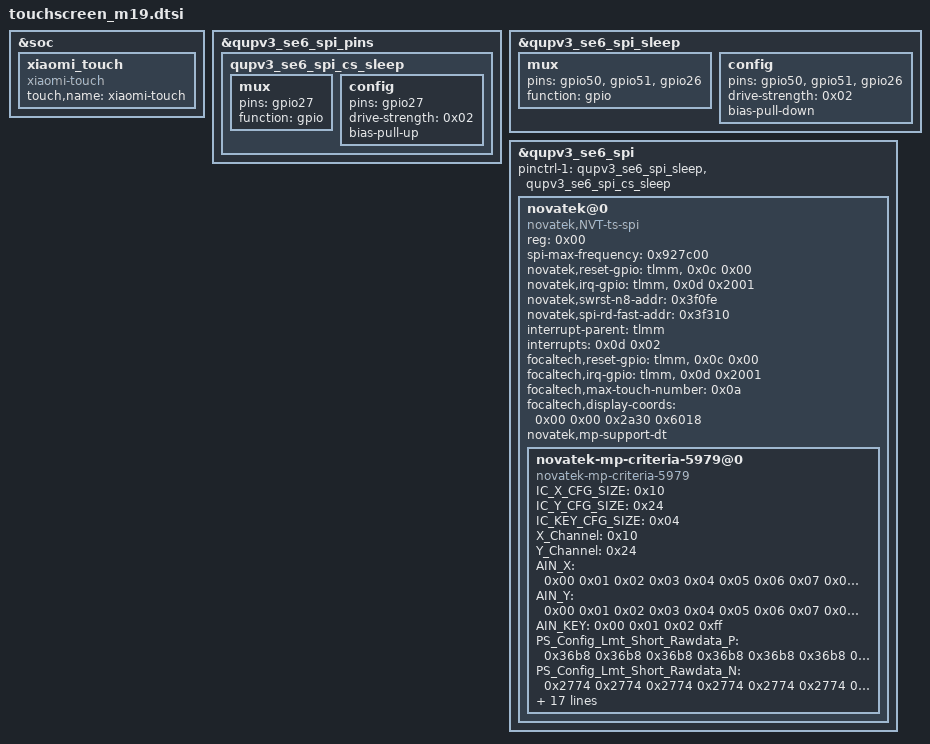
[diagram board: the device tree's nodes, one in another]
&soc {
	xiaomi_touch {
		status = "ok";
		compatible = "xiaomi-touch";
		touch,name = "xiaomi-touch";
	};
};

&qupv3_se6_spi_pins {
	qupv3_se6_spi_cs_sleep: qupv3_se6_spi_cs_sleep {
		mux {
			pins = "gpio27";
			function = "gpio";
		};

		config {
			pins = "gpio27";
			drive-strength = <0x02>;
			bias-pull-up;
		};
	};
};

&qupv3_se6_spi_sleep {
	mux {
		pins = "gpio50", "gpio51", "gpio26";
		function = "gpio";
	};

	config {
		pins = "gpio50", "gpio51", "gpio26";
		drive-strength = <0x02>;
		bias-pull-down;
	};
};


&qupv3_se6_spi {
			#address-cells = <0x01>;
			#size-cells = <0x00>;
			pinctrl-1 = <&qupv3_se6_spi_sleep>, <&qupv3_se6_spi_cs_sleep>;
			status = "okay";

			novatek@0 {
				compatible = "novatek,NVT-ts-spi", "focaltech,fts";
				reg = <0x00>;
				status = "ok";
				spi-max-frequency = <0x927c00>;
				novatek,reset-gpio = <&tlmm>, <0x0c 0x00>;
				novatek,irq-gpio = <&tlmm>, <0x0d 0x2001>;
				novatek,swrst-n8-addr = <0x3f0fe>;
				novatek,spi-rd-fast-addr = <0x3f310>;
				interrupt-parent = <&tlmm>;
				interrupts = <0x0d 0x02>;
				focaltech,reset-gpio = <&tlmm>, <0x0c 0x00>;
				focaltech,irq-gpio = <&tlmm>, <0x0d 0x2001>;
				focaltech,max-touch-number = <0x0a>;
				focaltech,display-coords = <0x00 0x00 0x2a30 0x6018>;
				novatek,mp-support-dt;

				novatek-mp-criteria-5979@0 {
					#address-cells = <0x01>;
					#size-cells = <0x00>;
					compatible = "novatek-mp-criteria-5979";
					IC_X_CFG_SIZE = <0x10>;
					IC_Y_CFG_SIZE = <0x24>;
					IC_KEY_CFG_SIZE = <0x04>;
					X_Channel = <0x10>;
					Y_Channel = <0x24>;
					AIN_X = <0x00 0x01 0x02 0x03 0x04 0x05 0x06 0x07 0x08 0x09 0x0a 0x0b 0x0c 0x0d 0x0e 0x0f>;
					AIN_Y = <0x00 0x01 0x02 0x03 0x04 0x05 0x06 0x07 0x08 0x09 0x0a 0x0b 0x0c 0x0d 0x0e 0x0f 0x10 0x11 0x12 0x13 0x14 0x15 0x16 0x17 0x18 0x19 0x1a 0x1b 0x1c 0x1d 0x1e 0x1f 0x20 0x21 0x22 0x23>;
					AIN_KEY = <0x00 0x01 0x02 0xff>;
					PS_Config_Lmt_Short_Rawdata_P = <0x36b8 0x36b8 0x36b8 0x36b8 0x36b8 0x36b8 0x36b8 0x36b8 0x36b8 0x36b8 0x36b8 0x36b8 0x36b8 0x36b8 0x36b8 0x36b8 0x36b8 0x36b8 0x36b8 0x36b8 0x36b8 0x36b8 0x36b8 0x36b8 0x36b8 0x36b8 0x36b8 0x36b8 0x36b8 0x36b8 0x36b8 0x36b8 0x36b8 0x36b8 0x36b8 0x36b8 0x36b8 0x36b8 0x36b8 0x36b8 0x36b8 0x36b8 0x36b8 0x36b8 0x36b8 0x36b8 0x36b8 0x36b8 0x36b8 0x36b8 0x36b8 0x36b8 0x36b8 0x36b8 0x36b8 0x36b8 0x36b8 0x36b8 0x36b8 0x36b8 0x36b8 0x36b8 0x36b8 0x36b8 0x36b8 0x36b8 0x36b8 0x36b8 0x36b8 0x36b8 0x36b8 0x36b8 0x36b8 0x36b8 0x36b8 0x36b8 0x36b8 0x36b8 0x36b8 0x36b8 0x36b8 0x36b8 0x36b8 0x36b8 0x36b8 0x36b8 0x36b8 0x36b8 0x36b8 0x36b8 0x36b8 0x36b8 0x36b8 0x36b8 0x36b8 0x36b8 0x36b8 0x36b8 0x36b8 0x36b8 0x36b8 0x36b8 0x36b8 0x36b8 0x36b8 0x36b8 0x36b8 0x36b8 0x36b8 0x36b8 0x36b8 0x36b8 0x36b8 0x36b8 0x36b8 0x36b8 0x36b8 0x36b8 0x36b8 0x36b8 0x36b8 0x36b8 0x36b8 0x36b8 0x36b8 0x36b8 0x36b8 0x36b8 0x36b8 0x36b8 0x36b8 0x36b8 0x36b8 0x36b8 0x36b8 0x36b8 0x36b8 0x36b8 0x36b8 0x36b8 0x36b8 0x36b8 0x36b8 0x36b8 0x36b8 0x36b8 0x36b8 0x36b8 0x36b8 0x36b8 0x36b8 0x36b8 0x36b8 0x36b8 0x36b8 0x36b8 0x36b8 0x36b8 0x36b8 0x36b8 0x36b8 0x36b8 0x36b8 0x36b8 0x36b8 0x36b8 0x36b8 0x36b8 0x36b8 0x36b8 0x36b8 0x36b8 0x36b8 0x36b8 0x36b8 0x36b8 0x36b8 0x36b8 0x36b8 0x36b8 0x36b8 0x36b8 0x36b8 0x36b8 0x36b8 0x36b8 0x36b8 0x36b8 0x36b8 0x36b8 0x36b8 0x36b8 0x36b8 0x36b8 0x36b8 0x36b8 0x36b8 0x36b8 0x36b8 0x36b8 0x36b8 0x36b8 0x36b8 0x36b8 0x36b8 0x36b8 0x36b8 0x36b8 0x36b8 0x36b8 0x36b8 0x36b8 0x36b8 0x36b8 0x36b8 0x36b8 0x36b8 0x36b8 0x36b8 0x36b8 0x36b8 0x36b8 0x36b8 0x36b8 0x36b8 0x36b8 0x36b8 0x36b8 0x36b8 0x36b8 0x36b8 0x36b8 0x36b8 0x36b8 0x36b8 0x36b8 0x36b8 0x36b8 0x36b8 0x36b8 0x36b8 0x36b8 0x36b8 0x36b8 0x36b8 0x36b8 0x36b8 0x36b8 0x36b8 0x36b8 0x36b8 0x36b8 0x36b8 0x36b8 0x36b8 0x36b8 0x36b8 0x36b8 0x36b8 0x36b8 0x36b8 0x36b8 0x36b8 0x36b8 0x36b8 0x36b8 0x36b8 0x36b8 0x36b8 0x36b8 0x36b8 0x36b8 0x36b8 0x36b8 0x36b8 0x36b8 0x36b8 0x36b8 0x36b8 0x36b8 0x36b8 0x36b8 0x36b8 0x36b8 0x36b8 0x36b8 0x36b8 0x36b8 0x36b8 0x36b8 0x36b8 0x36b8 0x36b8 0x36b8 0x36b8 0x36b8 0x36b8 0x36b8 0x36b8 0x36b8 0x36b8 0x36b8 0x36b8 0x36b8 0x36b8 0x36b8 0x36b8 0x36b8 0x36b8 0x36b8 0x36b8 0x36b8 0x36b8 0x36b8 0x36b8 0x36b8 0x36b8 0x36b8 0x36b8 0x36b8 0x36b8 0x36b8 0x36b8 0x36b8 0x36b8 0x36b8 0x36b8 0x36b8 0x36b8 0x36b8 0x36b8 0x36b8 0x36b8 0x36b8 0x36b8 0x36b8 0x36b8 0x36b8 0x36b8 0x36b8 0x36b8 0x36b8 0x36b8 0x36b8 0x36b8 0x36b8 0x36b8 0x36b8 0x36b8 0x36b8 0x36b8 0x36b8 0x36b8 0x36b8 0x36b8 0x36b8 0x36b8 0x36b8 0x36b8 0x36b8 0x36b8 0x36b8 0x36b8 0x36b8 0x36b8 0x36b8 0x36b8 0x36b8 0x36b8 0x36b8 0x36b8 0x36b8 0x36b8 0x36b8 0x36b8 0x36b8 0x36b8 0x36b8 0x36b8 0x36b8 0x36b8 0x36b8 0x36b8 0x36b8 0x36b8 0x36b8 0x36b8 0x36b8 0x36b8 0x36b8 0x36b8 0x36b8 0x36b8 0x36b8 0x36b8 0x36b8 0x36b8 0x36b8 0x36b8 0x36b8 0x36b8 0x36b8 0x36b8 0x36b8 0x36b8 0x36b8 0x36b8 0x36b8 0x36b8 0x36b8 0x36b8 0x36b8 0x36b8 0x36b8 0x36b8 0x36b8 0x36b8 0x36b8 0x36b8 0x36b8 0x36b8 0x36b8 0x36b8 0x36b8 0x36b8 0x36b8 0x36b8 0x36b8 0x36b8 0x36b8 0x36b8 0x36b8 0x36b8 0x36b8 0x36b8 0x36b8 0x36b8 0x36b8 0x36b8 0x36b8 0x36b8 0x36b8 0x36b8 0x36b8 0x36b8 0x36b8 0x36b8 0x36b8 0x36b8 0x36b8 0x36b8 0x36b8 0x36b8 0x36b8 0x36b8 0x36b8 0x36b8 0x36b8 0x36b8 0x36b8 0x36b8 0x36b8 0x36b8 0x36b8 0x36b8 0x36b8 0x36b8 0x36b8 0x36b8 0x36b8 0x36b8 0x36b8 0x36b8 0x36b8 0x36b8 0x36b8 0x36b8 0x36b8 0x36b8 0x36b8 0x36b8 0x36b8 0x36b8 0x36b8 0x36b8 0x36b8 0x36b8 0x36b8 0x36b8 0x36b8 0x36b8 0x36b8 0x36b8 0x36b8 0x36b8 0x36b8 0x36b8 0x36b8 0x36b8 0x36b8 0x36b8 0x36b8 0x36b8 0x36b8 0x36b8 0x36b8 0x36b8 0x36b8 0x36b8 0x36b8 0x36b8 0x36b8 0x36b8 0x36b8 0x36b8 0x36b8 0x36b8 0x36b8 0x36b8 0x36b8 0x36b8 0x36b8 0x36b8 0x36b8 0x36b8 0x36b8 0x36b8 0x36b8 0x36b8 0x36b8 0x36b8 0x36b8 0x36b8 0x36b8 0x36b8 0x36b8 0x36b8 0x36b8 0x36b8 0x36b8 0x36b8 0x36b8 0x36b8 0x36b8 0x36b8 0x36b8 0x36b8 0x36b8 0x36b8 0x36b8 0x36b8 0x36b8 0x36b8 0x36b8 0x36b8 0x36b8 0x36b8 0x36b8 0x36b8 0x36b8 0x36b8 0x36b8 0x36b8 0x36b8 0x36b8 0x36b8 0x36b8 0x36b8 0x36b8 0x36b8 0x36b8 0x36b8 0x36b8 0x36b8 0x36b8 0x36b8 0x36b8 0x36b8 0x36b8>;
					PS_Config_Lmt_Short_Rawdata_N = <0x2774 0x2774 0x2774 0x2774 0x2774 0x2774 0x2774 0x2774 0x2774 0x2774 0x2774 0x2774 0x2774 0x2774 0x2774 0x2774 0x2774 0x2774 0x2774 0x2774 0x2774 0x2774 0x2774 0x2774 0x2774 0x2774 0x2774 0x2774 0x2774 0x2774 0x2774 0x2774 0x2774 0x2774 0x2774 0x2774 0x2774 0x2774 0x2774 0x2774 0x2774 0x2774 0x2774 0x2774 0x2774 0x2774 0x2774 0x2774 0x2774 0x2774 0x2774 0x2774 0x2774 0x2774 0x2774 0x2774 0x2774 0x2774 0x2774 0x2774 0x2774 0x2774 0x2774 0x2774 0x2774 0x2774 0x2774 0x2774 0x2774 0x2774 0x2774 0x2774 0x2774 0x2774 0x2774 0x2774 0x2774 0x2774 0x2774 0x2774 0x2774 0x2774 0x2774 0x2774 0x2774 0x2774 0x2774 0x2774 0x2774 0x2774 0x2774 0x2774 0x2774 0x2774 0x2774 0x2774 0x2774 0x2774 0x2774 0x2774 0x2774 0x2774 0x2774 0x2774 0x2774 0x2774 0x2774 0x2774 0x2774 0x2774 0x2774 0x2774 0x2774 0x2774 0x2774 0x2774 0x2774 0x2774 0x2774 0x2774 0x2774 0x2774 0x2774 0x2774 0x2774 0x2774 0x2774 0x2774 0x2774 0x2774 0x2774 0x2774 0x2774 0x2774 0x2774 0x2774 0x2774 0x2774 0x2774 0x2774 0x2774 0x2774 0x2774 0x2774 0x2774 0x2774 0x2774 0x2774 0x2774 0x2774 0x2774 0x2774 0x2774 0x2774 0x2774 0x2774 0x2774 0x2774 0x2774 0x2774 0x2774 0x2774 0x2774 0x2774 0x2774 0x2774 0x2774 0x2774 0x2774 0x2774 0x2774 0x2774 0x2774 0x2774 0x2774 0x2774 0x2774 0x2774 0x2774 0x2774 0x2774 0x2774 0x2774 0x2774 0x2774 0x2774 0x2774 0x2774 0x2774 0x2774 0x2774 0x2774 0x2774 0x2774 0x2774 0x2774 0x2774 0x2774 0x2774 0x2774 0x2774 0x2774 0x2774 0x2774 0x2774 0x2774 0x2774 0x2774 0x2774 0x2774 0x2774 0x2774 0x2774 0x2774 0x2774 0x2774 0x2774 0x2774 0x2774 0x2774 0x2774 0x2774 0x2774 0x2774 0x2774 0x2774 0x2774 0x2774 0x2774 0x2774 0x2774 0x2774 0x2774 0x2774 0x2774 0x2774 0x2774 0x2774 0x2774 0x2774 0x2774 0x2774 0x2774 0x2774 0x2774 0x2774 0x2774 0x2774 0x2774 0x2774 0x2774 0x2774 0x2774 0x2774 0x2774 0x2774 0x2774 0x2774 0x2774 0x2774 0x2774 0x2774 0x2774 0x2774 0x2774 0x2774 0x2774 0x2774 0x2774 0x2774 0x2774 0x2774 0x2774 0x2774 0x2774 0x2774 0x2774 0x2774 0x2774 0x2774 0x2774 0x2774 0x2774 0x2774 0x2774 0x2774 0x2774 0x2774 0x2774 0x2774 0x2774 0x2774 0x2774 0x2774 0x2774 0x2774 0x2774 0x2774 0x2774 0x2774 0x2774 0x2774 0x2774 0x2774 0x2774 0x2774 0x2774 0x2774 0x2774 0x2774 0x2774 0x2774 0x2774 0x2774 0x2774 0x2774 0x2774 0x2774 0x2774 0x2774 0x2774 0x2774 0x2774 0x2774 0x2774 0x2774 0x2774 0x2774 0x2774 0x2774 0x2774 0x2774 0x2774 0x2774 0x2774 0x2774 0x2774 0x2774 0x2774 0x2774 0x2774 0x2774 0x2774 0x2774 0x2774 0x2774 0x2774 0x2774 0x2774 0x2774 0x2774 0x2774 0x2774 0x2774 0x2774 0x2774 0x2774 0x2774 0x2774 0x2774 0x2774 0x2774 0x2774 0x2774 0x2774 0x2774 0x2774 0x2774 0x2774 0x2774 0x2774 0x2774 0x2774 0x2774 0x2774 0x2774 0x2774 0x2774 0x2774 0x2774 0x2774 0x2774 0x2774 0x2774 0x2774 0x2774 0x2774 0x2774 0x2774 0x2774 0x2774 0x2774 0x2774 0x2774 0x2774 0x2774 0x2774 0x2774 0x2774 0x2774 0x2774 0x2774 0x2774 0x2774 0x2774 0x2774 0x2774 0x2774 0x2774 0x2774 0x2774 0x2774 0x2774 0x2774 0x2774 0x2774 0x2774 0x2774 0x2774 0x2774 0x2774 0x2774 0x2774 0x2774 0x2774 0x2774 0x2774 0x2774 0x2774 0x2774 0x2774 0x2774 0x2774 0x2774 0x2774 0x2774 0x2774 0x2774 0x2774 0x2774 0x2774 0x2774 0x2774 0x2774 0x2774 0x2774 0x2774 0x2774 0x2774 0x2774 0x2774 0x2774 0x2774 0x2774 0x2774 0x2774 0x2774 0x2774 0x2774 0x2774 0x2774 0x2774 0x2774 0x2774 0x2774 0x2774 0x2774 0x2774 0x2774 0x2774 0x2774 0x2774 0x2774 0x2774 0x2774 0x2774 0x2774 0x2774 0x2774 0x2774 0x2774 0x2774 0x2774 0x2774 0x2774 0x2774 0x2774 0x2774 0x2774 0x2774 0x2774 0x2774 0x2774 0x2774 0x2774 0x2774 0x2774 0x2774 0x2774 0x2774 0x2774 0x2774 0x2774 0x2774 0x2774 0x2774 0x2774 0x2774 0x2774 0x2774 0x2774 0x2774 0x2774 0x2774 0x2774 0x2774 0x2774 0x2774 0x2774 0x2774 0x2774 0x2774 0x2774 0x2774 0x2774 0x2774 0x2774 0x2774 0x2774 0x2774 0x2774 0x2774 0x2774 0x2774 0x2774 0x2774 0x2774 0x2774 0x2774 0x2774 0x2774 0x2774 0x2774 0x2774 0x2774 0x2774 0x2774 0x2774 0x2774 0x2774 0x2774 0x2774 0x2774 0x2774 0x2774 0x2774 0x2774 0x2774 0x2774 0x2774 0x2774 0x2774 0x2774 0x2774 0x2774 0x2774 0x2774 0x2774 0x2774 0x2774 0x2774 0x2774 0x2774 0x2774 0x2774 0x2774 0x2710 0x2710 0x2710>;
					PS_Config_Lmt_Open_Rawdata_P = <0xba7 0xbd9 0xc42 0xc75 0xc8b 0xc87 0xcbb 0xbe9 0xbd0 0xc55 0xc60 0xc42 0xc5c 0xc14 0xbd4 0xb99 0xbf8 0xc0c 0xc75 0xc9b 0xcbe 0xcb5 0xce2 0xc72 0xc49 0xc83 0xc8e 0xc6f 0xc86 0xc44 0xc0f 0xbf5 0xbfe 0xc24 0xc8e 0xcbe 0xce5 0xcd8 0xd0b 0xcd1 0xca3 0xcaa 0xcb7 0xc99 0xcb5 0xc60 0xc33 0xc11 0xc39 0xc44 0xcb2 0xcdf 0xd04 0xcf0 0xd1e 0xce1 0xcd4 0xcc3 0xcd4 0xcb8 0xcd3 0xc83 0xc59 0xc40 0xc50 0xc64 0xccc 0xcfb 0xd28 0xd16 0xd40 0xd02 0xd0c 0xcf7 0xd02 0xce9 0xcfb 0xca6 0xc7a 0xc63 0xc80 0xc73 0xcf0 0xd25 0xd59 0xd45 0xd67 0xd2b 0xd27 0xcf1 0xd13 0xcf7 0xd0d 0xcb2 0xc8a 0xc7a 0xc8e 0xcab 0xd0d 0xd3c 0xd78 0xd64 0xd8a 0xd43 0xd5f 0xd40 0xd47 0xd21 0xd30 0xcda 0xca7 0xc9c 0xcb1 0xcd0 0xd24 0xd59 0xda2 0xd8d 0xdb0 0xd61 0xd7d 0xd59 0xd4f 0xd37 0xd41 0xce6 0xcb7 0xcb5 0xcd8 0xd02 0xd67 0xd8a 0xdde 0xdc2 0xdf0 0xd98 0xdba 0xd8d 0xd97 0xd68 0xd6d 0xd0f 0xce5 0xcdc 0xcfa 0xd1d 0xd84 0xda5 0xdfb 0xdd7 0xe0b 0xdae 0xde8 0xdb8 0xdbb 0xd8b 0xd8a 0xd29 0xcfd 0xd04 0xd05 0xd40 0xda3 0xdad 0xe21 0xdfe 0xe2e 0xdd6 0xdf9 0xdd3 0xdd4 0xd8d 0xd98 0xd3d 0xd0b 0xd12 0xd21 0xd58 0xdb4 0xdde 0xe32 0xe0e 0xe3f 0xdde 0xe13 0xdeb 0xdec 0xdc5 0xdac 0xd4c 0xd1e 0xd2f 0xd4b 0xd89 0xded 0xe10 0xe5f 0xe48 0xe77 0xe04 0xe40 0xe17 0xe20 0xded 0xdc2 0xd72 0xd45 0xd4c 0xd68 0xda6 0xe10 0xe2e 0xe8c 0xe64 0xe9b 0xe1a 0xe5c 0xe33 0xe40 0xe0f 0xde5 0xd80 0xd58 0xd67 0xd6b 0xdb5 0xe1e 0xe40 0xea1 0xe77 0xeb3 0xe27 0xe8e 0xe60 0xe66 0xe38 0xe12 0xd9c 0xd7c 0xd84 0xd90 0xddb 0xe3f 0xe5d 0xec2 0xe74 0xed3 0xe46 0xeaa 0xe77 0xe82 0xe52 0xe23 0xd92 0xd8e 0xda2 0xd99 0xdf2 0xe4b 0xe6b 0xed6 0xeaf 0xeec 0xe58 0xecb 0xe9c 0xea1 0xe74 0xe3c 0xdc6 0xd90 0xdb1 0xdad 0xe09 0xe5b 0xe79 0xee8 0xec4 0xef3 0xe6d 0xed6 0xeac 0xeb0 0xe80 0xe4a 0xdda 0xd7c 0xda7 0xdf4 0xd8b 0xddf 0xddd 0xdf0 0xdd3 0xe0f 0xdf6 0xdaa 0xe08 0xe09 0xdd7 0xdf3 0xdc2 0xdd6 0xd8d 0xe41 0xdbf 0xe05 0xe04 0xe19 0xdfb 0xe35 0xe15 0xdd0 0xe23 0xe2e 0xdfa 0xe13 0xde2 0xdf3 0xdaa 0xe3a 0xddd 0xe15 0xe0f 0xe2a 0xe08 0xe44 0xe05 0xdf3 0xe3d 0xe51 0xe21 0xe3a 0xe0c 0xe19 0xda2 0xe4a 0xded 0xe27 0xe1a 0xe36 0xe19 0xe55 0xe25 0xe01 0xe4b 0xe62 0xe36 0xe4f 0xe21 0xe24 0xdd6 0xe55 0xe12 0xe46 0xe38 0xe58 0xe32 0xe6b 0xe3a 0xe20 0xe69 0xe78 0xe5b 0xe70 0xe39 0xe3f 0xde8 0xe64 0xe23 0xe56 0xe4e 0xe67 0xe44 0xe7e 0xe4d 0xe32 0xe6d 0xe80 0xe5f 0xe74 0xe3d 0xe41 0xdf2 0xe62 0xe35 0xe67 0xe5f 0xe7b 0xe58 0xe8d 0xe5d 0xe4f 0xe85 0xe94 0xe77 0xe8e 0xe60 0xe60 0xe0b 0xe8e 0xe64 0xe91 0xe8a 0xea6 0xe83 0xeb1 0xe85 0xe60 0xe89 0xe9a 0xe79 0xe93 0xe5f 0xe60 0xe0b 0xe6e 0xe54 0xe85 0xe7e 0xe9b 0xe71 0xea6 0xe77 0xe78 0xe9e 0xeb7 0xe95 0xeb1 0xe7b 0xe83 0xe20 0xe87 0xe6a 0xe9e 0xe93 0xeb3 0xe8c 0xebf 0xe8a 0xe7e 0xe9f 0xeb4 0xe94 0xeac 0xe7c 0xe82 0xe2a 0xe90 0xe8c 0xeb7 0xeb6 0xecc 0xea5 0xed9 0xea1 0xe90 0xeb1 0xec2 0xeaa 0xec1 0xe91 0xe94 0xe33 0xe8a 0xe82 0xeb3 0xeb7 0xecc 0xe9f 0xed9 0xe9e 0xe8e 0xea9 0xeb7 0xe9f 0xeb8 0xe87 0xe87 0xe38 0xe85 0xe8e 0xec5 0xebf 0xed6 0xead 0xee2 0xea2 0xe9c 0xeb7 0xecc 0xeaf 0xec5 0xe9e 0xe8e 0xe41 0xe89 0xe93 0xecd 0xec9 0xede 0xeb8 0xee7 0xea6 0xea3 0xebb 0xecb 0xeb3 0xec9 0xe9e 0xe90 0xe4a 0xe94 0xea8 0xeeb 0xee2 0xefa 0xed2 0xf03 0xebb 0xebb 0xecf 0xede 0xec2 0xedb 0xeb0 0xe9e 0xe51 0xec6 0xed9 0xf27 0xf23 0xf32 0xf11 0xf47 0xefc 0xefe 0xf12 0xf1c 0xf01 0xf16 0xee7 0xecf 0xe86 0xe91 0xed9 0xf26 0xf23 0xf35 0xf13 0xf46 0xefc 0xf07 0xf20 0xf23 0xf0f 0xf24 0xef7 0xed3 0xe67 0xcea 0xdd1 0xe80 0xf59 0xf6a 0xf44 0xf75 0xf24 0xf2a 0xf47 0xf4a 0xf31 0xf47 0xe63 0xd89 0xce2 0x1400 0x1400 0x1400>;
					PS_Config_Lmt_Open_Rawdata_N = <0x4fe 0x514 0x541 0x556 0x560 0x55e 0x574 0x51a 0x510 0x549 0x54d 0x541 0x54c 0x52d 0x511 0x4f8 0x521 0x529 0x556 0x567 0x576 0x572 0x585 0x555 0x544 0x55c 0x561 0x554 0x55e 0x541 0x52b 0x520 0x523 0x534 0x561 0x576 0x586 0x581 0x597 0x57e 0x56a 0x56d 0x573 0x566 0x572 0x54d 0x53a 0x52c 0x53d 0x541 0x571 0x584 0x594 0x58b 0x59f 0x585 0x57f 0x578 0x57f 0x573 0x57f 0x55c 0x54a 0x540 0x547 0x54f 0x57c 0x590 0x5a3 0x59b 0x5ad 0x593 0x597 0x58e 0x593 0x588 0x590 0x56b 0x559 0x54f 0x55b 0x556 0x58b 0x5a2 0x5b8 0x5b0 0x5be 0x5a4 0x5a3 0x58c 0x59a 0x58e 0x598 0x571 0x55f 0x559 0x561 0x56e 0x598 0x5ac 0x5c5 0x5bd 0x5cd 0x5af 0x5bb 0x5ad 0x5b0 0x5a0 0x5a7 0x582 0x56c 0x567 0x570 0x57d 0x5a1 0x5b8 0x5d7 0x5ce 0x5dd 0x5bc 0x5c8 0x5b8 0x5b4 0x5aa 0x5ae 0x587 0x573 0x572 0x581 0x593 0x5be 0x5cd 0x5f1 0x5e5 0x5f9 0x5d3 0x5e2 0x5ce 0x5d3 0x5bf 0x5c1 0x598 0x586 0x583 0x58f 0x59e 0x5cb 0x5d9 0x5fe 0x5ee 0x604 0x5dd 0x5f5 0x5e1 0x5e2 0x5ce 0x5cd 0x5a4 0x591 0x594 0x594 0x5ad 0x5d8 0x5dc 0x60e 0x5ff 0x613 0x5ee 0x5fd 0x5ec 0x5ed 0x5ce 0x5d3 0x5ac 0x597 0x59a 0x5a0 0x5b8 0x5df 0x5f1 0x615 0x606 0x61b 0x5f1 0x608 0x5f7 0x5f7 0x5e6 0x5dc 0x5b3 0x59f 0x5a6 0x5b2 0x5cd 0x5f8 0x607 0x628 0x61f 0x633 0x601 0x61b 0x60a 0x60d 0x5f8 0x5e5 0x5c3 0x5b0 0x5b3 0x5bf 0x5d9 0x607 0x613 0x63c 0x62b 0x642 0x60b 0x627 0x616 0x61b 0x606 0x5f4 0x5c9 0x5b8 0x5be 0x5c0 0x5e0 0x60d 0x61b 0x645 0x633 0x64c 0x610 0x63d 0x629 0x62b 0x618 0x607 0x5d5 0x5c7 0x5cb 0x5d0 0x5f0 0x61b 0x628 0x653 0x631 0x65a 0x61e 0x649 0x633 0x637 0x623 0x60f 0x5d1 0x5cf 0x5d7 0x5d4 0x5fa 0x620 0x62e 0x65b 0x64b 0x665 0x625 0x657 0x643 0x645 0x631 0x619 0x5e7 0x5d0 0x5de 0x5dc 0x604 0x627 0x634 0x663 0x654 0x668 0x62e 0x65b 0x649 0x64b 0x637 0x61f 0x5ef 0x5c7 0x5da 0x5fb 0x5ce 0x5f2 0x5f1 0x5f9 0x5ec 0x606 0x5fb 0x5db 0x603 0x604 0x5ee 0x5fa 0x5e5 0x5ee 0x5ce 0x61c 0x5e4 0x602 0x601 0x60a 0x5fe 0x616 0x609 0x5eb 0x60f 0x613 0x5fd 0x608 0x5f3 0x5fa 0x5db 0x619 0x5f1 0x609 0x606 0x612 0x603 0x61d 0x602 0x5fa 0x61a 0x622 0x60e 0x619 0x605 0x60a 0x5d7 0x61f 0x5f8 0x610 0x60b 0x617 0x60a 0x624 0x610 0x600 0x620 0x62a 0x617 0x622 0x60e 0x60f 0x5ee 0x624 0x607 0x61e 0x618 0x625 0x615 0x62e 0x619 0x60d 0x62d 0x633 0x627 0x630 0x618 0x61b 0x5f5 0x62b 0x60f 0x625 0x621 0x62c 0x61d 0x636 0x621 0x615 0x62e 0x637 0x628 0x631 0x61a 0x61c 0x5fa 0x62a 0x616 0x62c 0x628 0x634 0x625 0x63c 0x628 0x622 0x639 0x63f 0x633 0x63d 0x629 0x629 0x604 0x63d 0x62b 0x63e 0x63b 0x647 0x638 0x64c 0x639 0x629 0x63a 0x642 0x634 0x63f 0x628 0x629 0x604 0x62f 0x624 0x639 0x636 0x642 0x630 0x647 0x633 0x633 0x643 0x64e 0x640 0x64c 0x634 0x638 0x60d 0x63a 0x62d 0x643 0x63f 0x64c 0x63c 0x652 0x63b 0x636 0x644 0x64d 0x63f 0x649 0x635 0x637 0x612 0x63d 0x63c 0x64e 0x64e 0x657 0x646 0x65d 0x645 0x63d 0x64c 0x653 0x649 0x652 0x63e 0x63f 0x616 0x63b 0x637 0x64c 0x64e 0x657 0x644 0x65d 0x643 0x63d 0x648 0x64e 0x644 0x64f 0x63a 0x63a 0x618 0x639 0x63d 0x654 0x652 0x65b 0x64a 0x661 0x645 0x643 0x64e 0x657 0x64b 0x654 0x643 0x63d 0x61c 0x63a 0x63f 0x658 0x656 0x65f 0x64f 0x663 0x647 0x646 0x650 0x657 0x64c 0x656 0x643 0x63d 0x61f 0x63f 0x648 0x664 0x661 0x66b 0x65a 0x66f 0x650 0x650 0x658 0x65f 0x653 0x65e 0x64b 0x643 0x622 0x655 0x65d 0x67e 0x67c 0x683 0x675 0x68c 0x66c 0x66d 0x675 0x679 0x66e 0x677 0x663 0x658 0x639 0x63e 0x65d 0x67e 0x67c 0x684 0x676 0x68b 0x66c 0x670 0x67b 0x67c 0x674 0x67d 0x66a 0x65a 0x62c 0x589 0x5ec 0x637 0x694 0x69b 0x68b 0x6a0 0x67d 0x67f 0x68c 0x68d 0x682 0x68c 0x62a 0x5cd 0x585 0xfffffe01 0xfffffe01 0xfffffe01>;
					PS_Config_Lmt_FW_Rawdata_P = <0x460 0x454 0x453 0x45a 0x452 0x45a 0x457 0x459 0x468 0x467 0x465 0x45b 0x467 0x462 0x453 0x454 0x45e 0x456 0x456 0x45a 0x457 0x45a 0x457 0x45d 0x460 0x457 0x457 0x460 0x45a 0x45e 0x45e 0x45e 0x45b 0x461 0x461 0x45e 0x45e 0x45d 0x45e 0x459 0x450 0x44f 0x44c 0x453 0x44f 0x44f 0x452 0x45b 0x464 0x454 0x459 0x459 0x453 0x45a 0x457 0x460 0x460 0x45e 0x45d 0x45d 0x45b 0x457 0x457 0x462 0x45b 0x459 0x457 0x457 0x456 0x457 0x456 0x459 0x45d 0x453 0x457 0x45b 0x457 0x453 0x457 0x469 0x461 0x45d 0x461 0x45b 0x460 0x460 0x460 0x457 0x454 0x452 0x450 0x450 0x450 0x453 0x456 0x462 0x460 0x457 0x454 0x457 0x459 0x456 0x457 0x457 0x45b 0x457 0x454 0x453 0x457 0x454 0x457 0x462 0x465 0x459 0x459 0x45a 0x456 0x45b 0x459 0x460 0x460 0x45b 0x45d 0x45b 0x45e 0x45d 0x45d 0x45e 0x45e 0x44c 0x453 0x450 0x457 0x456 0x456 0x456 0x454 0x456 0x456 0x457 0x454 0x456 0x454 0x461 0x46c 0x453 0x454 0x456 0x453 0x45a 0x454 0x45b 0x457 0x457 0x459 0x459 0x454 0x459 0x454 0x462 0x45e 0x454 0x450 0x452 0x450 0x454 0x453 0x457 0x45a 0x452 0x453 0x452 0x454 0x450 0x454 0x45d 0x461 0x457 0x459 0x459 0x454 0x45d 0x45a 0x460 0x457 0x457 0x453 0x453 0x456 0x457 0x457 0x462 0x468 0x453 0x452 0x453 0x454 0x459 0x457 0x45d 0x45b 0x45a 0x459 0x459 0x45d 0x45b 0x45e 0x45d 0x462 0x45b 0x45d 0x45d 0x45b 0x45b 0x45d 0x460 0x457 0x454 0x456 0x457 0x457 0x45a 0x45a 0x465 0x461 0x45b 0x45b 0x45b 0x45d 0x456 0x457 0x460 0x462 0x464 0x462 0x461 0x468 0x45d 0x460 0x461 0x460 0x45d 0x461 0x462 0x45e 0x468 0x469 0x460 0x456 0x456 0x457 0x453 0x457 0x454 0x454 0x45e 0x45e 0x452 0x44f 0x44f 0x450 0x456 0x454 0x45d 0x453 0x450 0x45a 0x45d 0x459 0x460 0x456 0x465 0x462 0x453 0x456 0x45a 0x45e 0x461 0x464 0x460 0x45d 0x45e 0x459 0x459 0x459 0x45b 0x45b 0x464 0x461 0x457 0x45a 0x45d 0x45a 0x45d 0x462 0x45d 0x465 0x45d 0x45b 0x454 0x459 0x454 0x453 0x464 0x46b 0x453 0x459 0x457 0x457 0x456 0x456 0x453 0x45d 0x45b 0x45b 0x459 0x45a 0x45b 0x45d 0x45b 0x45e 0x450 0x454 0x453 0x456 0x456 0x454 0x456 0x45d 0x460 0x45e 0x465 0x45e 0x45d 0x45d 0x45d 0x456 0x457 0x456 0x454 0x450 0x452 0x462 0x461 0x462 0x461 0x460 0x454 0x45a 0x457 0x45a 0x465 0x468 0x450 0x44f 0x450 0x450 0x454 0x459 0x45b 0x46b 0x462 0x467 0x45a 0x461 0x460 0x45a 0x45e 0x464 0x461 0x464 0x464 0x461 0x460 0x45e 0x45e 0x45d 0x461 0x461 0x461 0x461 0x461 0x461 0x459 0x460 0x454 0x457 0x456 0x457 0x453 0x461 0x460 0x462 0x462 0x462 0x460 0x461 0x464 0x465 0x45b 0x460 0x462 0x462 0x465 0x462 0x45e 0x461 0x461 0x465 0x462 0x464 0x45e 0x465 0x465 0x464 0x45e 0x460 0x467 0x461 0x465 0x464 0x462 0x45a 0x45d 0x468 0x467 0x468 0x465 0x467 0x467 0x46c 0x459 0x45e 0x465 0x464 0x464 0x467 0x465 0x460 0x461 0x462 0x462 0x462 0x45e 0x462 0x468 0x465 0x45b 0x45d 0x45a 0x460 0x456 0x45e 0x457 0x45b 0x456 0x45b 0x459 0x459 0x459 0x45a 0x45b 0x461 0x467 0x462 0x460 0x45e 0x464 0x461 0x45d 0x461 0x460 0x45b 0x45b 0x45a 0x45d 0x45d 0x45a 0x45a 0x462 0x464 0x454 0x459 0x452 0x459 0x459 0x453 0x457 0x456 0x456 0x456 0x457 0x453 0x452 0x452 0x46b 0x465 0x453 0x45d 0x453 0x45e 0x452 0x450 0x454 0x465 0x45a 0x459 0x45b 0x45a 0x45a 0x45d 0x45e 0x467 0x45e 0x45a 0x45e 0x459 0x457 0x462 0x45d 0x45e 0x45e 0x45e 0x45e 0x45e 0x464 0x462 0x464 0x45e 0x45a 0x462 0x45e 0x45e 0x45e 0x461 0x460 0x461 0x45b 0x456 0x45a 0x45a 0x462 0x45e 0x467 0x45e 0x459 0x460 0x457 0x45a 0x454 0x45b 0x457 0x45e 0x460 0x45b 0x45e 0x460 0x461 0x45d 0x467 0x45e 0x45e 0x45e 0x460 0x461 0x45b 0x45e 0x464 0x45e 0x46b 0x462 0x469 0x464 0x45e 0x45b 0x457 0xf00 0xf00 0xf00>;
					PS_Config_Lmt_FW_Rawdata_N = <0x1e0 0x1db 0x1da 0x1dd 0x1da 0x1dd 0x1dc 0x1dd 0x1e3 0x1e3 0x1e2 0x1de 0x1e3 0x1e1 0x1da 0x1db 0x1df 0x1db 0x1db 0x1dd 0x1dc 0x1dd 0x1dc 0x1de 0x1e0 0x1dc 0x1dc 0x1e0 0x1dd 0x1df 0x1df 0x1df 0x1de 0x1e0 0x1e0 0x1df 0x1df 0x1de 0x1df 0x1dd 0x1d9 0x1d8 0x1d7 0x1da 0x1d8 0x1d8 0x1da 0x1de 0x1e1 0x1db 0x1dd 0x1dd 0x1da 0x1dd 0x1dc 0x1e0 0x1e0 0x1df 0x1de 0x1de 0x1de 0x1dc 0x1dc 0x1e1 0x1de 0x1dd 0x1dc 0x1dc 0x1db 0x1dc 0x1db 0x1dd 0x1de 0x1da 0x1dc 0x1de 0x1dc 0x1da 0x1dc 0x1e4 0x1e0 0x1de 0x1e0 0x1de 0x1e0 0x1e0 0x1e0 0x1dc 0x1db 0x1da 0x1d9 0x1d9 0x1d9 0x1da 0x1db 0x1e1 0x1e0 0x1dc 0x1db 0x1dc 0x1dd 0x1db 0x1dc 0x1dc 0x1de 0x1dc 0x1db 0x1da 0x1dc 0x1db 0x1dc 0x1e1 0x1e2 0x1dd 0x1dd 0x1dd 0x1db 0x1de 0x1dd 0x1e0 0x1e0 0x1de 0x1de 0x1de 0x1df 0x1de 0x1de 0x1df 0x1df 0x1d7 0x1da 0x1d9 0x1dc 0x1db 0x1db 0x1db 0x1db 0x1db 0x1db 0x1dc 0x1db 0x1db 0x1db 0x1e0 0x1e5 0x1da 0x1db 0x1db 0x1da 0x1dd 0x1db 0x1de 0x1dc 0x1dc 0x1dd 0x1dd 0x1db 0x1dd 0x1db 0x1e1 0x1df 0x1db 0x1d9 0x1da 0x1d9 0x1db 0x1da 0x1dc 0x1dd 0x1da 0x1da 0x1da 0x1db 0x1d9 0x1db 0x1de 0x1e0 0x1dc 0x1dd 0x1dd 0x1db 0x1de 0x1dd 0x1e0 0x1dc 0x1dc 0x1da 0x1da 0x1db 0x1dc 0x1dc 0x1e1 0x1e3 0x1da 0x1da 0x1da 0x1db 0x1dd 0x1dc 0x1de 0x1de 0x1dd 0x1dd 0x1dd 0x1de 0x1de 0x1df 0x1de 0x1e1 0x1de 0x1de 0x1de 0x1de 0x1de 0x1de 0x1e0 0x1dc 0x1db 0x1db 0x1dc 0x1dc 0x1dd 0x1dd 0x1e2 0x1e0 0x1de 0x1de 0x1de 0x1de 0x1db 0x1dc 0x1e0 0x1e1 0x1e1 0x1e1 0x1e0 0x1e3 0x1de 0x1e0 0x1e0 0x1e0 0x1de 0x1e0 0x1e1 0x1df 0x1e3 0x1e4 0x1e0 0x1db 0x1db 0x1dc 0x1da 0x1dc 0x1db 0x1db 0x1df 0x1df 0x1da 0x1d8 0x1d8 0x1d9 0x1db 0x1db 0x1de 0x1da 0x1d9 0x1dd 0x1de 0x1dd 0x1e0 0x1db 0x1e2 0x1e1 0x1da 0x1db 0x1dd 0x1df 0x1e0 0x1e1 0x1e0 0x1de 0x1df 0x1dd 0x1dd 0x1dd 0x1de 0x1de 0x1e1 0x1e0 0x1dc 0x1dd 0x1de 0x1dd 0x1de 0x1e1 0x1de 0x1e2 0x1de 0x1de 0x1db 0x1dd 0x1db 0x1da 0x1e1 0x1e4 0x1da 0x1dd 0x1dc 0x1dc 0x1db 0x1db 0x1da 0x1de 0x1de 0x1de 0x1dd 0x1dd 0x1de 0x1de 0x1de 0x1df 0x1d9 0x1db 0x1da 0x1db 0x1db 0x1db 0x1db 0x1de 0x1e0 0x1df 0x1e2 0x1df 0x1de 0x1de 0x1de 0x1db 0x1dc 0x1db 0x1db 0x1d9 0x1da 0x1e1 0x1e0 0x1e1 0x1e0 0x1e0 0x1db 0x1dd 0x1dc 0x1dd 0x1e2 0x1e3 0x1d9 0x1d8 0x1d9 0x1d9 0x1db 0x1dd 0x1de 0x1e4 0x1e1 0x1e3 0x1dd 0x1e0 0x1e0 0x1dd 0x1df 0x1e1 0x1e0 0x1e1 0x1e1 0x1e0 0x1e0 0x1df 0x1df 0x1de 0x1e0 0x1e0 0x1e0 0x1e0 0x1e0 0x1e0 0x1dd 0x1e0 0x1db 0x1dc 0x1db 0x1dc 0x1da 0x1e0 0x1e0 0x1e1 0x1e1 0x1e1 0x1e0 0x1e0 0x1e1 0x1e2 0x1de 0x1e0 0x1e1 0x1e1 0x1e2 0x1e1 0x1df 0x1e0 0x1e0 0x1e2 0x1e1 0x1e1 0x1df 0x1e2 0x1e2 0x1e1 0x1df 0x1e0 0x1e3 0x1e0 0x1e2 0x1e1 0x1e1 0x1dd 0x1de 0x1e3 0x1e3 0x1e3 0x1e2 0x1e3 0x1e3 0x1e5 0x1dd 0x1df 0x1e2 0x1e1 0x1e1 0x1e3 0x1e2 0x1e0 0x1e0 0x1e1 0x1e1 0x1e1 0x1df 0x1e1 0x1e3 0x1e2 0x1de 0x1de 0x1dd 0x1e0 0x1db 0x1df 0x1dc 0x1de 0x1db 0x1de 0x1dd 0x1dd 0x1dd 0x1dd 0x1de 0x1e0 0x1e3 0x1e1 0x1e0 0x1df 0x1e1 0x1e0 0x1de 0x1e0 0x1e0 0x1de 0x1de 0x1dd 0x1de 0x1de 0x1dd 0x1dd 0x1e1 0x1e1 0x1db 0x1dd 0x1da 0x1dd 0x1dd 0x1da 0x1dc 0x1db 0x1db 0x1db 0x1dc 0x1da 0x1da 0x1da 0x1e4 0x1e2 0x1da 0x1de 0x1da 0x1df 0x1da 0x1d9 0x1db 0x1e2 0x1dd 0x1dd 0x1de 0x1dd 0x1dd 0x1de 0x1df 0x1e3 0x1df 0x1dd 0x1df 0x1dd 0x1dc 0x1e1 0x1de 0x1df 0x1df 0x1df 0x1df 0x1df 0x1e1 0x1e1 0x1e1 0x1df 0x1dd 0x1e1 0x1df 0x1df 0x1df 0x1e0 0x1e0 0x1e0 0x1de 0x1db 0x1dd 0x1dd 0x1e1 0x1df 0x1e3 0x1df 0x1dd 0x1e0 0x1dc 0x1dd 0x1db 0x1de 0x1dc 0x1df 0x1e0 0x1de 0x1df 0x1e0 0x1e0 0x1de 0x1e3 0x1df 0x1df 0x1df 0x1e0 0x1e0 0x1de 0x1df 0x1e1 0x1df 0x1e4 0x1e1 0x1e4 0x1e1 0x1df 0x1de 0x1dc 0xf0 0xf0 0xf0>;
					PS_Config_Lmt_FW_CC_P = <0x29 0x2a 0x2a 0x2a 0x2a 0x2a 0x2a 0x2a 0x2a 0x2a 0x2a 0x2a 0x2a 0x2a 0x2a 0x29 0x2a 0x2a 0x2a 0x2a 0x29 0x2a 0x2a 0x2a 0x2a 0x29 0x29 0x29 0x29 0x29 0x29 0x2a 0x2a 0x29 0x29 0x29 0x29 0x29 0x29 0x29 0x2a 0x2a 0x2a 0x29 0x2a 0x2a 0x29 0x2a 0x2c 0x2a 0x2a 0x2a 0x2a 0x2a 0x2a 0x2a 0x2a 0x2a 0x2a 0x2a 0x2a 0x2a 0x2a 0x2a 0x2a 0x29 0x29 0x2a 0x29 0x2a 0x29 0x2a 0x2a 0x2a 0x2a 0x2a 0x2a 0x2a 0x2a 0x2a 0x2c 0x2a 0x2a 0x2a 0x2a 0x2a 0x2a 0x2a 0x2a 0x2a 0x2a 0x2a 0x2a 0x2a 0x2a 0x2a 0x2a 0x2a 0x29 0x29 0x29 0x29 0x29 0x29 0x2a 0x2a 0x2a 0x2a 0x2a 0x2a 0x2a 0x2a 0x2c 0x2a 0x2a 0x2a 0x2a 0x2a 0x2a 0x2a 0x2a 0x2a 0x2a 0x2a 0x2a 0x2a 0x2a 0x2c 0x2a 0x2a 0x2a 0x2a 0x2a 0x2a 0x2a 0x2a 0x2a 0x2a 0x2a 0x2a 0x2a 0x2a 0x2a 0x2c 0x2a 0x2a 0x2a 0x2a 0x2a 0x2a 0x2a 0x2a 0x2a 0x2a 0x2a 0x2a 0x2a 0x2a 0x2a 0x2c 0x2a 0x2a 0x2a 0x2a 0x2a 0x2a 0x2a 0x2a 0x2a 0x2a 0x2a 0x2a 0x2a 0x2a 0x2a 0x2c 0x2c 0x2a 0x2a 0x2a 0x2a 0x2a 0x2a 0x2a 0x2a 0x2a 0x2a 0x2a 0x2a 0x2a 0x2a 0x2c 0x2a 0x2a 0x2a 0x2a 0x2a 0x2a 0x2a 0x2a 0x2a 0x2a 0x2a 0x2a 0x2a 0x2a 0x2a 0x2c 0x2c 0x2a 0x2a 0x2a 0x2a 0x2a 0x2a 0x2c 0x2a 0x2a 0x2a 0x2a 0x2a 0x2a 0x2a 0x2c 0x2a 0x2a 0x2a 0x2a 0x2a 0x2a 0x2a 0x2a 0x2a 0x2a 0x2a 0x2a 0x2a 0x2a 0x2a 0x2c 0x2c 0x2a 0x2a 0x2a 0x2a 0x2a 0x2a 0x2c 0x2a 0x2a 0x2a 0x2a 0x2a 0x2a 0x2a 0x2c 0x2a 0x2a 0x2a 0x2a 0x2a 0x2a 0x2a 0x2a 0x2a 0x2a 0x2a 0x2a 0x2a 0x2a 0x2a 0x2c 0x2c 0x2a 0x2a 0x2a 0x2a 0x2a 0x2a 0x2c 0x2a 0x2a 0x2a 0x2a 0x2a 0x2a 0x2a 0x2c 0x2c 0x2a 0x29 0x29 0x29 0x2a 0x2a 0x29 0x2a 0x2a 0x2a 0x2a 0x2a 0x2a 0x2a 0x2c 0x2c 0x2a 0x2a 0x2a 0x2a 0x2a 0x2a 0x2a 0x2c 0x2a 0x2a 0x2a 0x2a 0x2a 0x2a 0x2c 0x2c 0x2a 0x2a 0x2a 0x2a 0x2a 0x2a 0x2a 0x2a 0x2a 0x2a 0x2a 0x2a 0x2a 0x2a 0x2c 0x2c 0x2a 0x2a 0x2a 0x2a 0x2a 0x2a 0x2a 0x2c 0x2a 0x2a 0x2a 0x2a 0x2a 0x2a 0x2c 0x2c 0x2a 0x2a 0x2a 0x2a 0x2a 0x2a 0x2a 0x2a 0x2a 0x2a 0x2a 0x2a 0x2a 0x2a 0x2c 0x2c 0x2a 0x2a 0x2a 0x2a 0x2a 0x2c 0x2c 0x2c 0x2a 0x2a 0x2a 0x2a 0x2a 0x2a 0x2c 0x2c 0x2a 0x2a 0x2a 0x2a 0x2a 0x2a 0x2a 0x2c 0x2a 0x2a 0x2a 0x2a 0x2a 0x2a 0x2c 0x2d 0x2a 0x2a 0x2a 0x2a 0x2a 0x2c 0x2c 0x2c 0x2a 0x2a 0x2a 0x2a 0x2a 0x2a 0x2c 0x2c 0x2a 0x2a 0x2a 0x2a 0x2a 0x2a 0x2a 0x2a 0x2a 0x2c 0x2a 0x2c 0x2c 0x2c 0x2c 0x2d 0x2a 0x2c 0x2a 0x2a 0x2a 0x2c 0x2c 0x2c 0x2a 0x2a 0x2a 0x2a 0x2a 0x2a 0x2c 0x2c 0x2a 0x2a 0x2a 0x2a 0x2a 0x2a 0x2a 0x2a 0x2a 0x2a 0x2a 0x2a 0x2a 0x2a 0x2c 0x2c 0x2a 0x2c 0x2a 0x2a 0x2a 0x2a 0x2a 0x2a 0x2a 0x2a 0x2a 0x2a 0x2a 0x2a 0x2c 0x2c 0x2a 0x2a 0x2a 0x2a 0x2a 0x2a 0x2a 0x2a 0x2a 0x2a 0x2a 0x2a 0x2a 0x2a 0x2c 0x2c 0x2a 0x2a 0x2a 0x2a 0x2a 0x2a 0x2a 0x2a 0x2a 0x2a 0x2a 0x2a 0x2a 0x2a 0x2c 0x2c 0x2a 0x2a 0x2a 0x2a 0x2a 0x2a 0x2a 0x2a 0x2a 0x2a 0x2a 0x2a 0x2a 0x2a 0x2c 0x2c 0x2a 0x2c 0x2a 0x2a 0x2a 0x2a 0x2a 0x2a 0x2a 0x2a 0x2a 0x2a 0x2a 0x2a 0x2c 0x2c 0x2a 0x2a 0x2a 0x2a 0x2a 0x2a 0x2a 0x2a 0x2a 0x2a 0x2a 0x2a 0x2a 0x2a 0x2c 0x2a 0x2a 0x2a 0x2a 0x2c 0x2c 0x2c 0x2c 0x2c 0x2c 0x2a 0x2c 0x2a 0x2a 0x2a 0x2a 0x13a 0x13a 0x13a>;
					PS_Config_Lmt_FW_CC_N = <0x12 0x13 0x13 0x13 0x13 0x13 0x13 0x13 0x13 0x13 0x13 0x13 0x13 0x13 0x13 0x12 0x13 0x13 0x13 0x13 0x12 0x13 0x13 0x13 0x13 0x12 0x12 0x12 0x12 0x12 0x12 0x13 0x13 0x12 0x12 0x12 0x12 0x12 0x12 0x12 0x13 0x13 0x13 0x12 0x13 0x13 0x12 0x13 0x13 0x13 0x13 0x13 0x13 0x13 0x13 0x13 0x13 0x13 0x13 0x13 0x13 0x13 0x13 0x13 0x13 0x12 0x12 0x13 0x12 0x13 0x12 0x13 0x13 0x13 0x13 0x13 0x13 0x13 0x13 0x13 0x13 0x13 0x13 0x13 0x13 0x13 0x13 0x13 0x13 0x13 0x13 0x13 0x13 0x13 0x13 0x13 0x13 0x13 0x12 0x12 0x12 0x12 0x12 0x12 0x13 0x13 0x13 0x13 0x13 0x13 0x13 0x13 0x13 0x13 0x13 0x13 0x13 0x13 0x13 0x13 0x13 0x13 0x13 0x13 0x13 0x13 0x13 0x13 0x13 0x13 0x13 0x13 0x13 0x13 0x13 0x13 0x13 0x13 0x13 0x13 0x13 0x13 0x13 0x13 0x13 0x13 0x13 0x13 0x13 0x13 0x13 0x13 0x13 0x13 0x13 0x13 0x13 0x13 0x13 0x13 0x13 0x13 0x13 0x13 0x13 0x13 0x13 0x13 0x13 0x13 0x13 0x13 0x13 0x13 0x13 0x13 0x13 0x13 0x13 0x13 0x13 0x13 0x13 0x13 0x13 0x13 0x13 0x13 0x13 0x13 0x13 0x13 0x13 0x13 0x13 0x13 0x13 0x13 0x13 0x13 0x13 0x13 0x13 0x13 0x13 0x13 0x13 0x13 0x13 0x13 0x13 0x13 0x13 0x13 0x13 0x13 0x13 0x13 0x13 0x13 0x13 0x13 0x13 0x13 0x13 0x13 0x13 0x13 0x13 0x13 0x13 0x13 0x13 0x13 0x13 0x13 0x13 0x13 0x13 0x13 0x13 0x13 0x13 0x13 0x13 0x13 0x13 0x13 0x13 0x13 0x13 0x13 0x13 0x13 0x13 0x13 0x13 0x13 0x13 0x13 0x13 0x13 0x13 0x13 0x13 0x13 0x13 0x13 0x13 0x13 0x13 0x13 0x13 0x13 0x13 0x13 0x13 0x13 0x13 0x13 0x13 0x13 0x13 0x13 0x13 0x13 0x13 0x13 0x13 0x13 0x12 0x12 0x12 0x13 0x13 0x12 0x13 0x13 0x13 0x13 0x13 0x13 0x13 0x13 0x13 0x13 0x13 0x13 0x13 0x13 0x13 0x13 0x13 0x13 0x13 0x13 0x13 0x13 0x13 0x13 0x13 0x13 0x13 0x13 0x13 0x13 0x13 0x13 0x13 0x13 0x13 0x13 0x13 0x13 0x13 0x13 0x13 0x13 0x13 0x13 0x13 0x13 0x13 0x13 0x13 0x13 0x13 0x13 0x13 0x13 0x13 0x13 0x13 0x13 0x13 0x13 0x13 0x13 0x13 0x13 0x13 0x13 0x13 0x13 0x13 0x13 0x13 0x13 0x13 0x13 0x13 0x13 0x13 0x13 0x13 0x13 0x13 0x13 0x13 0x13 0x13 0x13 0x13 0x13 0x13 0x13 0x13 0x13 0x13 0x13 0x13 0x13 0x13 0x13 0x13 0x13 0x13 0x13 0x13 0x13 0x14 0x13 0x13 0x13 0x13 0x13 0x13 0x13 0x13 0x13 0x13 0x13 0x13 0x13 0x13 0x13 0x13 0x13 0x13 0x13 0x13 0x13 0x13 0x13 0x13 0x13 0x13 0x13 0x13 0x13 0x13 0x13 0x14 0x13 0x13 0x13 0x13 0x13 0x13 0x13 0x13 0x13 0x13 0x13 0x13 0x13 0x13 0x13 0x13 0x13 0x13 0x13 0x13 0x13 0x13 0x13 0x13 0x13 0x13 0x13 0x13 0x13 0x13 0x13 0x13 0x13 0x13 0x13 0x13 0x13 0x13 0x13 0x13 0x13 0x13 0x13 0x13 0x13 0x13 0x13 0x13 0x13 0x13 0x13 0x13 0x13 0x13 0x13 0x13 0x13 0x13 0x13 0x13 0x13 0x13 0x13 0x13 0x13 0x13 0x13 0x13 0x13 0x13 0x13 0x13 0x13 0x13 0x13 0x13 0x13 0x13 0x13 0x13 0x13 0x13 0x13 0x13 0x13 0x13 0x13 0x13 0x13 0x13 0x13 0x13 0x13 0x13 0x13 0x13 0x13 0x13 0x13 0x13 0x13 0x13 0x13 0x13 0x13 0x13 0x13 0x13 0x13 0x13 0x13 0x13 0x13 0x13 0x13 0x13 0x13 0x13 0x13 0x13 0x13 0x13 0x13 0x13 0x13 0x13 0x13 0x13 0x13 0x13 0x13 0x13 0x13 0x13 0x13 0x13 0x13 0x13 0x13 0x13 0x13 0x13 0x13 0x00 0x00 0x00>;
					PS_Config_Lmt_FW_Diff_P = <0x32 0x32 0x32 0x32 0x32 0x32 0x32 0x32 0x32 0x32 0x32 0x32 0x32 0x32 0x32 0x32 0x32 0x32 0x32 0x32 0x32 0x32 0x32 0x32 0x32 0x32 0x32 0x32 0x32 0x32 0x32 0x32 0x32 0x32 0x32 0x32 0x32 0x32 0x32 0x32 0x32 0x32 0x32 0x32 0x32 0x32 0x32 0x32 0x32 0x32 0x32 0x32 0x32 0x32 0x32 0x32 0x32 0x32 0x32 0x32 0x32 0x32 0x32 0x32 0x32 0x32 0x32 0x32 0x32 0x32 0x32 0x32 0x32 0x32 0x32 0x32 0x32 0x32 0x32 0x32 0x32 0x32 0x32 0x32 0x32 0x32 0x32 0x32 0x32 0x32 0x32 0x32 0x32 0x32 0x32 0x32 0x32 0x32 0x32 0x32 0x32 0x32 0x32 0x32 0x32 0x32 0x32 0x32 0x32 0x32 0x32 0x32 0x32 0x32 0x32 0x32 0x32 0x32 0x32 0x32 0x32 0x32 0x32 0x32 0x32 0x32 0x32 0x32 0x32 0x32 0x32 0x32 0x32 0x32 0x32 0x32 0x32 0x32 0x32 0x32 0x32 0x32 0x32 0x32 0x32 0x32 0x32 0x32 0x32 0x32 0x32 0x32 0x32 0x32 0x32 0x32 0x32 0x32 0x32 0x32 0x32 0x32 0x32 0x32 0x32 0x32 0x32 0x32 0x32 0x32 0x32 0x32 0x32 0x32 0x32 0x32 0x32 0x32 0x32 0x32 0x32 0x32 0x32 0x32 0x32 0x32 0x32 0x32 0x32 0x32 0x32 0x32 0x32 0x32 0x32 0x32 0x32 0x32 0x32 0x32 0x32 0x32 0x32 0x32 0x32 0x32 0x32 0x32 0x32 0x32 0x32 0x32 0x32 0x32 0x32 0x32 0x32 0x32 0x32 0x32 0x32 0x32 0x32 0x32 0x32 0x32 0x32 0x32 0x32 0x32 0x32 0x32 0x32 0x32 0x32 0x32 0x32 0x32 0x32 0x32 0x32 0x32 0x32 0x32 0x32 0x32 0x32 0x32 0x32 0x32 0x32 0x32 0x32 0x32 0x32 0x32 0x32 0x32 0x32 0x32 0x32 0x32 0x32 0x32 0x32 0x32 0x32 0x32 0x32 0x32 0x32 0x32 0x32 0x32 0x32 0x32 0x32 0x32 0x32 0x32 0x32 0x32 0x32 0x32 0x32 0x32 0x32 0x32 0x32 0x32 0x32 0x32 0x32 0x32 0x32 0x32 0x32 0x32 0x32 0x32 0x32 0x32 0x32 0x32 0x32 0x32 0x32 0x32 0x32 0x32 0x32 0x32 0x32 0x32 0x32 0x32 0x32 0x32 0x32 0x32 0x32 0x32 0x32 0x32 0x32 0x32 0x32 0x32 0x32 0x32 0x32 0x32 0x32 0x32 0x32 0x32 0x32 0x32 0x32 0x32 0x32 0x32 0x32 0x32 0x32 0x32 0x32 0x32 0x32 0x32 0x32 0x32 0x32 0x32 0x32 0x32 0x32 0x32 0x32 0x32 0x32 0x32 0x32 0x32 0x32 0x32 0x32 0x32 0x32 0x32 0x32 0x32 0x32 0x32 0x32 0x32 0x32 0x32 0x32 0x32 0x32 0x32 0x32 0x32 0x32 0x32 0x32 0x32 0x32 0x32 0x32 0x32 0x32 0x32 0x32 0x32 0x32 0x32 0x32 0x32 0x32 0x32 0x32 0x32 0x32 0x32 0x32 0x32 0x32 0x32 0x32 0x32 0x32 0x32 0x32 0x32 0x32 0x32 0x32 0x32 0x32 0x32 0x32 0x32 0x32 0x32 0x32 0x32 0x32 0x32 0x32 0x32 0x32 0x32 0x32 0x32 0x32 0x32 0x32 0x32 0x32 0x32 0x32 0x32 0x32 0x32 0x32 0x32 0x32 0x32 0x32 0x32 0x32 0x32 0x32 0x32 0x32 0x32 0x32 0x32 0x32 0x32 0x32 0x32 0x32 0x32 0x32 0x32 0x32 0x32 0x32 0x32 0x32 0x32 0x32 0x32 0x32 0x32 0x32 0x32 0x32 0x32 0x32 0x32 0x32 0x32 0x32 0x32 0x32 0x32 0x32 0x32 0x32 0x32 0x32 0x32 0x32 0x32 0x32 0x32 0x32 0x32 0x32 0x32 0x32 0x32 0x32 0x32 0x32 0x32 0x32 0x32 0x32 0x32 0x32 0x32 0x32 0x32 0x32 0x32 0x32 0x32 0x32 0x32 0x32 0x32 0x32 0x32 0x32 0x32 0x32 0x32 0x32 0x32 0x32 0x32 0x32 0x32 0x32 0x32 0x32 0x32 0x32 0x32 0x32 0x32 0x32 0x32 0x32 0x32 0x32 0x32 0x32 0x32 0x32 0x32 0x32 0x32 0x32 0x32 0x32 0x32 0x32 0x32 0x32 0x32 0x32 0x32 0x32 0x32 0x32 0x32 0x32 0x32 0x32 0x32 0x4b 0x4b 0x4b>;
					PS_Config_Lmt_FW_Diff_N = <0xffffffce 0xffffffce 0xffffffce 0xffffffce 0xffffffce 0xffffffce 0xffffffce 0xffffffce 0xffffffce 0xffffffce 0xffffffce 0xffffffce 0xffffffce 0xffffffce 0xffffffce 0xffffffce 0xffffffce 0xffffffce 0xffffffce 0xffffffce 0xffffffce 0xffffffce 0xffffffce 0xffffffce 0xffffffce 0xffffffce 0xffffffce 0xffffffce 0xffffffce 0xffffffce 0xffffffce 0xffffffce 0xffffffce 0xffffffce 0xffffffce 0xffffffce 0xffffffce 0xffffffce 0xffffffce 0xffffffce 0xffffffce 0xffffffce 0xffffffce 0xffffffce 0xffffffce 0xffffffce 0xffffffce 0xffffffce 0xffffffce 0xffffffce 0xffffffce 0xffffffce 0xffffffce 0xffffffce 0xffffffce 0xffffffce 0xffffffce 0xffffffce 0xffffffce 0xffffffce 0xffffffce 0xffffffce 0xffffffce 0xffffffce 0xffffffce 0xffffffce 0xffffffce 0xffffffce 0xffffffce 0xffffffce 0xffffffce 0xffffffce 0xffffffce 0xffffffce 0xffffffce 0xffffffce 0xffffffce 0xffffffce 0xffffffce 0xffffffce 0xffffffce 0xffffffce 0xffffffce 0xffffffce 0xffffffce 0xffffffce 0xffffffce 0xffffffce 0xffffffce 0xffffffce 0xffffffce 0xffffffce 0xffffffce 0xffffffce 0xffffffce 0xffffffce 0xffffffce 0xffffffce 0xffffffce 0xffffffce 0xffffffce 0xffffffce 0xffffffce 0xffffffce 0xffffffce 0xffffffce 0xffffffce 0xffffffce 0xffffffce 0xffffffce 0xffffffce 0xffffffce 0xffffffce 0xffffffce 0xffffffce 0xffffffce 0xffffffce 0xffffffce 0xffffffce 0xffffffce 0xffffffce 0xffffffce 0xffffffce 0xffffffce 0xffffffce 0xffffffce 0xffffffce 0xffffffce 0xffffffce 0xffffffce 0xffffffce 0xffffffce 0xffffffce 0xffffffce 0xffffffce 0xffffffce 0xffffffce 0xffffffce 0xffffffce 0xffffffce 0xffffffce 0xffffffce 0xffffffce 0xffffffce 0xffffffce 0xffffffce 0xffffffce 0xffffffce 0xffffffce 0xffffffce 0xffffffce 0xffffffce 0xffffffce 0xffffffce 0xffffffce 0xffffffce 0xffffffce 0xffffffce 0xffffffce 0xffffffce 0xffffffce 0xffffffce 0xffffffce 0xffffffce 0xffffffce 0xffffffce 0xffffffce 0xffffffce 0xffffffce 0xffffffce 0xffffffce 0xffffffce 0xffffffce 0xffffffce 0xffffffce 0xffffffce 0xffffffce 0xffffffce 0xffffffce 0xffffffce 0xffffffce 0xffffffce 0xffffffce 0xffffffce 0xffffffce 0xffffffce 0xffffffce 0xffffffce 0xffffffce 0xffffffce 0xffffffce 0xffffffce 0xffffffce 0xffffffce 0xffffffce 0xffffffce 0xffffffce 0xffffffce 0xffffffce 0xffffffce 0xffffffce 0xffffffce 0xffffffce 0xffffffce 0xffffffce 0xffffffce 0xffffffce 0xffffffce 0xffffffce 0xffffffce 0xffffffce 0xffffffce 0xffffffce 0xffffffce 0xffffffce 0xffffffce 0xffffffce 0xffffffce 0xffffffce 0xffffffce 0xffffffce 0xffffffce 0xffffffce 0xffffffce 0xffffffce 0xffffffce 0xffffffce 0xffffffce 0xffffffce 0xffffffce 0xffffffce 0xffffffce 0xffffffce 0xffffffce 0xffffffce 0xffffffce 0xffffffce 0xffffffce 0xffffffce 0xffffffce 0xffffffce 0xffffffce 0xffffffce 0xffffffce 0xffffffce 0xffffffce 0xffffffce 0xffffffce 0xffffffce 0xffffffce 0xffffffce 0xffffffce 0xffffffce 0xffffffce 0xffffffce 0xffffffce 0xffffffce 0xffffffce 0xffffffce 0xffffffce 0xffffffce 0xffffffce 0xffffffce 0xffffffce 0xffffffce 0xffffffce 0xffffffce 0xffffffce 0xffffffce 0xffffffce 0xffffffce 0xffffffce 0xffffffce 0xffffffce 0xffffffce 0xffffffce 0xffffffce 0xffffffce 0xffffffce 0xffffffce 0xffffffce 0xffffffce 0xffffffce 0xffffffce 0xffffffce 0xffffffce 0xffffffce 0xffffffce 0xffffffce 0xffffffce 0xffffffce 0xffffffce 0xffffffce 0xffffffce 0xffffffce 0xffffffce 0xffffffce 0xffffffce 0xffffffce 0xffffffce 0xffffffce 0xffffffce 0xffffffce 0xffffffce 0xffffffce 0xffffffce 0xffffffce 0xffffffce 0xffffffce 0xffffffce 0xffffffce 0xffffffce 0xffffffce 0xffffffce 0xffffffce 0xffffffce 0xffffffce 0xffffffce 0xffffffce 0xffffffce 0xffffffce 0xffffffce 0xffffffce 0xffffffce 0xffffffce 0xffffffce 0xffffffce 0xffffffce 0xffffffce 0xffffffce 0xffffffce 0xffffffce 0xffffffce 0xffffffce 0xffffffce 0xffffffce 0xffffffce 0xffffffce 0xffffffce 0xffffffce 0xffffffce 0xffffffce 0xffffffce 0xffffffce 0xffffffce 0xffffffce 0xffffffce 0xffffffce 0xffffffce 0xffffffce 0xffffffce 0xffffffce 0xffffffce 0xffffffce 0xffffffce 0xffffffce 0xffffffce 0xffffffce 0xffffffce 0xffffffce 0xffffffce 0xffffffce 0xffffffce 0xffffffce 0xffffffce 0xffffffce 0xffffffce 0xffffffce 0xffffffce 0xffffffce 0xffffffce 0xffffffce 0xffffffce 0xffffffce 0xffffffce 0xffffffce 0xffffffce 0xffffffce 0xffffffce 0xffffffce 0xffffffce 0xffffffce 0xffffffce 0xffffffce 0xffffffce 0xffffffce 0xffffffce 0xffffffce 0xffffffce 0xffffffce 0xffffffce 0xffffffce 0xffffffce 0xffffffce 0xffffffce 0xffffffce 0xffffffce 0xffffffce 0xffffffce 0xffffffce 0xffffffce 0xffffffce 0xffffffce 0xffffffce 0xffffffce 0xffffffce 0xffffffce 0xffffffce 0xffffffce 0xffffffce 0xffffffce 0xffffffce 0xffffffce 0xffffffce 0xffffffce 0xffffffce 0xffffffce 0xffffffce 0xffffffce 0xffffffce 0xffffffce 0xffffffce 0xffffffce 0xffffffce 0xffffffce 0xffffffce 0xffffffce 0xffffffce 0xffffffce 0xffffffce 0xffffffce 0xffffffce 0xffffffce 0xffffffce 0xffffffce 0xffffffce 0xffffffce 0xffffffce 0xffffffce 0xffffffce 0xffffffce 0xffffffce 0xffffffce 0xffffffce 0xffffffce 0xffffffce 0xffffffce 0xffffffce 0xffffffce 0xffffffce 0xffffffce 0xffffffce 0xffffffce 0xffffffce 0xffffffce 0xffffffce 0xffffffce 0xffffffce 0xffffffce 0xffffffce 0xffffffce 0xffffffce 0xffffffce 0xffffffce 0xffffffce 0xffffffce 0xffffffce 0xffffffce 0xffffffce 0xffffffce 0xffffffce 0xffffffce 0xffffffce 0xffffffce 0xffffffce 0xffffffce 0xffffffce 0xffffffce 0xffffffce 0xffffffce 0xffffffce 0xffffffce 0xffffffce 0xffffffce 0xffffffce 0xffffffce 0xffffffce 0xffffffce 0xffffffce 0xffffffce 0xffffffce 0xffffffce 0xffffffce 0xffffffce 0xffffffce 0xffffffce 0xffffffce 0xffffffce 0xffffffce 0xffffffce 0xffffffce 0xffffffce 0xffffffce 0xffffffce 0xffffffce 0xffffffce 0xffffffce 0xffffffce 0xffffffce 0xffffffce 0xffffffce 0xffffffce 0xffffffce 0xffffffce 0xffffffce 0xffffffce 0xffffffce 0xffffffce 0xffffffce 0xffffffce 0xffffffce 0xffffffce 0xffffffce 0xffffffce 0xffffffce 0xffffffce 0xffffffce 0xffffffce 0xffffffce 0xffffffce 0xffffffce 0xffffffce 0xffffffce 0xffffffce 0xffffffce 0xffffffce 0xffffffce 0xffffffce 0xffffffce 0xffffffce 0xffffffce 0xffffffce 0xffffffce 0xffffffce 0xffffffce 0xffffffce 0xffffffce 0xffffffce 0xffffffce 0xffffffce 0xffffffce 0xffffffce 0xffffffce 0xffffffce 0xffffffce 0xffffffce 0xffffffce 0xffffffce 0xffffffce 0xffffffce 0xffffffce 0xffffffce 0xffffffce 0xffffffce 0xffffffce 0xffffffce 0xffffffce 0xffffffce 0xffffffce 0xffffffce 0xffffffce 0xffffffce 0xffffffce 0xffffffce 0xffffffce 0xffffffce 0xffffffb5 0xffffffb5 0xffffffb5>;
					PS_Config_Diff_Test_Frame = <0x32>;
				};
			};
};
